AUTOSAR XML (schema 4-3-0)
package /ARRoot
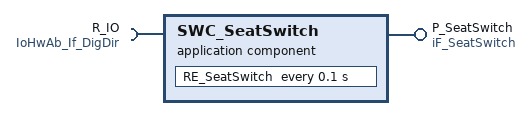
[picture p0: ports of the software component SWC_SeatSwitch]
  application sw component type SWC_SeatSwitch
    provide port P_SeatSwitch: nonqueued-sender-com-spec=PassengerDetected, provided-interface=iF_SeatSwitch
    require port R_IO: client-com-spec=ReadDirect, required-interface=IoHwAb_If_DigDir
    behavior InternalBehavior
      timing event TE_RE_SeatSwitch: start-on-event=RE_SeatSwitch, period=0.1
      runnable RE_SeatSwitch: symbol=SeatSwitch_func
        data-send-points:
          access DSP_RE_SeatSwitch_P_SeatSwitch_PassengerDetected: accessed-variable=P_SeatSwitch.PassengerDetected, scope=COMMUNICATION-INTER-ECU
        sync call SSCP_RE_SeatSwitch_R_IO_ReadDirect: operation=R_IO.ReadDirect
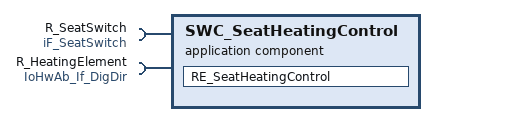
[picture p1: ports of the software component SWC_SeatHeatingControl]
  application sw component type SWC_SeatHeatingControl
    require port R_SeatSwitch: nonqueued-receiver-com-spec=PassengerDetected, required-interface=iF_SeatSwitch
    require port R_HeatingElement: client-com-spec=WriteDirect, required-interface=IoHwAb_If_DigDir
    behavior InternalBehavior
      data received event DRE_RE_SeatHeatingControl_R_SeatSwitch_PassengerDetected: start-on-event=RE_SeatHeatingControl, data=R_SeatSwitch.PassengerDetected
      runnable RE_SeatHeatingControl: symbol=SeatHeatingControl_func
        data-receive-point-by-arguments:
          access DRPBA_RE_SeatHeatingControl_R_SeatSwitch_PassengerDetected: accessed-variable=R_SeatSwitch.PassengerDetected, scope=COMMUNICATION-INTER-ECU
        sync call SSCP_RE_SeatHeatingControl_R_HeatingElement_WriteDirect: operation=R_HeatingElement.WriteDirect
  composition sw component type CSWC_SeatHeatingSystem
    component SWC_SeatSwitch: type=SWC_SeatSwitch
    component SWC_SeatHeatingControl: type=SWC_SeatHeatingControl
    connect SWC_SeatSwitch.P_SeatSwitch -> SWC_SeatHeatingControl.R_SeatSwitch
  sender receiver interface iF_SeatSwitch
    data PassengerDetected: type=boolean
